AUTOSAR XML (schema 4-2-1)
package /ComponentTypes
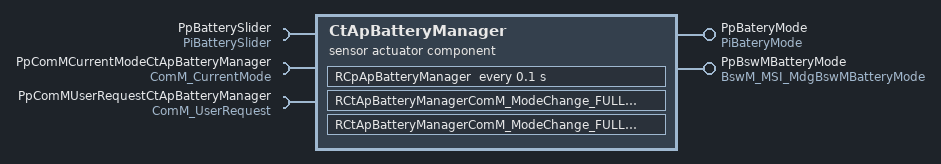
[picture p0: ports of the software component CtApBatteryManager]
  sensor actuator sw component type CtApBatteryManager
    provide port PpBateryMode: nonqueued-sender-com-spec{data-element=DeBateryMode, init-value=1}, provided-interface=PiBateryMode
    provide port PpBswMBatteryMode: mode-switch-sender-com-spec{enhanced-mode-api=false, mode-group=BswM_MDGP_MdgBswMBatteryMode, queue-length=1}, provided-interface=BswM_MSI_MdgBswMBatteryMode
    require port PpBatterySlider: required-interface=PiBatterySlider
    require port PpComMCurrentModeCtApBatteryManager: mode-switch-receiver-com-spec{enhanced-mode-api=false, supports-asynchronous-mode-switch=false}, required-interface=ComM_CurrentMode
    require port PpComMUserRequestCtApBatteryManager: required-interface=ComM_UserRequest
    behavior CtApBatteryManager_InternalBehavior
      timing event TMT_RCpApBatteryManager: start-on-event=RCpApBatteryManager, period=0.1
      swc mode switch event MST_RCtApBatteryManagerComM_ModeChange_FULL_COMM_Entry_0: start-on-event=RCtApBatteryManagerComM_ModeChange_FULL_COMM_Entry, activation=ON-ENTRY, mode=PpComMCurrentModeCtApBatteryManager.currentMode.COMM_FULL_COMMUNICATION
      swc mode switch event MST_RCtApBatteryManagerComM_ModeChange_FULL_COMM_Exit_0: start-on-event=RCtApBatteryManagerComM_ModeChange_FULL_COMM_Exit, activation=ON-ENTRY, mode=PpComMCurrentModeCtApBatteryManager.currentMode.COMM_NO_COMMUNICATION
      runnable RCpApBatteryManager
        data-send-points:
          access SEND_PpBateryMode_DeBateryMode: accessed-variable=PpBateryMode.DeBateryMode
        mode switch point SWITCH_PpBswMBatteryMode_BswM_MDGP_MdgBswMBatteryMode: mode-group=PpBswMBatteryMode.BswM_MDGP_MdgBswMBatteryMode
        sync call SC_PpBatterySlider_ReadChannel: operation=PpBatterySlider.ReadChannel, timeout=0
        sync call SC_PpComMUserRequestCtApBatteryManager_RequestComMode: operation=PpComMUserRequestCtApBatteryManager.RequestComMode, timeout=0
      runnable RCtApBatteryManagerComM_ModeChange_FULL_COMM_Entry
        data-send-points:
          access SEND_PpBateryMode_DeBateryMode: accessed-variable=PpBateryMode.DeBateryMode
      runnable RCtApBatteryManagerComM_ModeChange_FULL_COMM_Exit
        data-send-points:
          access SEND_PpBateryMode_DeBateryMode: accessed-variable=PpBateryMode.DeBateryMode
  swc implementation CtApBatteryManager_Implementation: behavior=CtApBatteryManager_InternalBehavior
    code-descriptors:
      code Default: artifact-descriptors=autosar-engineering-object={short-label=Default, category=SWSRC}
